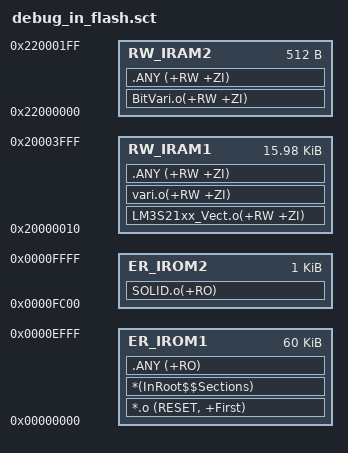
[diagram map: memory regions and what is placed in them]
				 ; *************************************************************
; *** Scatter-Loading Description File generated by uVision ***
; *************************************************************
; RAM空间留12个字节 给位变量
LR_IROM1 0x00000000 0x0000F000  
 {    ; load region size_region
  ER_IROM1 0x00000000 0x0000F000  
   {  ; load address = execution address
    *.o (RESET, +First)
    *(InRoot$$Sections)
    .ANY (+RO)
   }
  ER_IROM2 0x0000FC00 0x00000400  
   {  ; load address = execution address
    SOLID.o(+RO) 
   }

  RW_IRAM1 0x20000010 0x00003ff0  
   {  ; RW data
    LM3S21xx_Vect.o(+RW +ZI)
    vari.o(+RW +ZI)
    .ANY (+RW +ZI)
   }
  RW_IRAM2 0x22000000 0x00000200  
   {  ; RW data
    BitVari.o(+RW +ZI)
    .ANY (+RW +ZI)
   }
}

